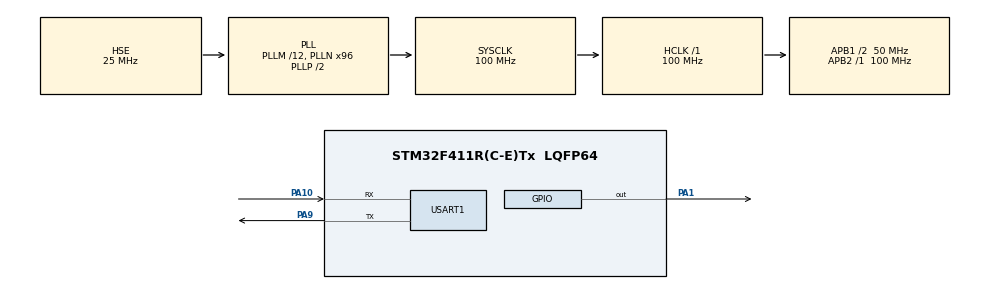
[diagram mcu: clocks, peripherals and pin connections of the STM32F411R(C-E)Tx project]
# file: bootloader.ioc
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Dma.Request0=USART1_RX
Dma.USART1_RX.0.Direction=DMA_PERIPH_TO_MEMORY
Dma.USART1_RX.0.FIFOMode=DMA_FIFOMODE_DISABLE
Dma.USART1_RX.0.Instance=DMA2_Stream2
Dma.USART1_RX.0.MemDataAlignment=DMA_MDATAALIGN_BYTE
Dma.USART1_RX.0.MemInc=DMA_MINC_ENABLE
Dma.USART1_RX.0.Mode=DMA_NORMAL
Dma.USART1_RX.0.PeriphDataAlignment=DMA_PDATAALIGN_BYTE
Dma.USART1_RX.0.PeriphInc=DMA_PINC_DISABLE
Dma.USART1_RX.0.Priority=DMA_PRIORITY_LOW
Mcu.Family=STM32F4
Mcu.Name=STM32F411R(C-E)Tx
Mcu.Package=LQFP64
NVIC.DMA2_Stream2_IRQn=true\:0\:0\:false\:false\:true\:false\:true\:true
NVIC.PriorityGroup=NVIC_PRIORITYGROUP_4
NVIC.USART1_IRQn=true\:0\:0\:false\:false\:true\:false\:true\:true
PA1.Signal=GPIO_Output
PA10.Mode=Asynchronous
PA10.Signal=USART1_RX
PA13.Mode=Serial_Wire
PA13.Signal=SYS_JTMS-SWDIO
PA14.Mode=Serial_Wire
PA14.Signal=SYS_JTCK-SWCLK
PA9.Mode=Asynchronous
PA9.Signal=USART1_TX
PC14-OSC32_IN.Mode=LSE-External-Oscillator
PC14-OSC32_IN.Signal=RCC_OSC32_IN
PC15-OSC32_OUT.Mode=LSE-External-Oscillator
PC15-OSC32_OUT.Signal=RCC_OSC32_OUT
PH0\ -\ OSC_IN.Mode=HSE-External-Oscillator
PH0\ -\ OSC_IN.Signal=RCC_OSC_IN
PH1\ -\ OSC_OUT.Mode=HSE-External-Oscillator
PH1\ -\ OSC_OUT.Signal=RCC_OSC_OUT
ProjectManager.HeapSize=0x200
ProjectManager.StackSize=0x400
ProjectManager.TargetToolchain=MDK-ARM V5.32
RCC.48MHZClocksFreq_Value=50000000
RCC.AHBFreq_Value=100000000
RCC.APB1CLKDivider=RCC_HCLK_DIV2
RCC.APB1Freq_Value=50000000
RCC.APB1TimFreq_Value=100000000
RCC.APB2Freq_Value=100000000
RCC.APB2TimFreq_Value=100000000
RCC.CortexFreq_Value=100000000
RCC.HCLKFreq_Value=100000000
RCC.HSE_VALUE=25000000
RCC.HSI_VALUE=16000000
RCC.PLLM=12
RCC.PLLN=96
RCC.PLLSourceVirtual=RCC_PLLSOURCE_HSE
RCC.SYSCLKFreq_VALUE=100000000
RCC.SYSCLKSource=RCC_SYSCLKSOURCE_PLLCLK
RCC.VCOOutputFreq_Value=200000000
USART1.VirtualMode=VM_ASYNC
board=custom

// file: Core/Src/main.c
/* USER CODE BEGIN Header */
/**
  ******************************************************************************
  * @file           : main.c
  * @brief          : Main program body
  ******************************************************************************
  * @attention
  *
  * Copyright (c) 2026 STMicroelectronics.
  * All rights reserved.
  *
  * This software is licensed under terms that can be found in the LICENSE file
  * in the root directory of this software component.
  * If no LICENSE file comes with this software, it is provided AS-IS.
  *
  ******************************************************************************
  */
/* USER CODE END Header */
#include "main.h"
#include "dma.h"
#include "usart.h"
#include "gpio.h"

/* USER CODE BEGIN Includes */
#include "string.h"
#include "flash_if.h"
#include "protocol.h"
/* USER CODE END Includes */

/* USER CODE BEGIN PD */
/* After reset, wait this long for an upgrade request before booting the app */
#define BOOT_UPGRADE_WINDOW_MS   5000U
/* USER CODE END PD */

/* USER CODE BEGIN PV */
/* TX self-test array: ASCII part is readable in text mode,
   raw bytes are readable in HEX mode */

/* USER CODE END PV */

void SystemClock_Config(void);
/* USER CODE BEGIN PFP */
static uint8_t Boot_IsAppValid(uint32_t app_addr);
static int flag;
/* USER CODE END PFP */

int main(void)
{

  /* MCU Configuration--------------------------------------------------------*/

  /* Reset of all peripherals, Initializes the Flash interface and the Systick. */
  HAL_Init();

  /* Configure the system clock */
  SystemClock_Config();

  /* Initialize all configured peripherals */
  MX_GPIO_Init();
  MX_DMA_Init();
  MX_USART1_UART_Init();
  /* USER CODE BEGIN 2 */
  /*
   * Boot decision:
   *   1. Run area has a valid image -> wait up to 5 s for an upgrade
   *      request. If no frame arrives, boot the application.
   *   2. Run area is blank/invalid but the storage area holds the factory
   *      image -> erase the run area, copy the storage image there, boot it.
   *   3. Neither area is valid -> stay here and wait for OTA.
   */
  if (Boot_IsAppValid(ADDR_RUN) != 0U)
  {
    uint32_t window_start = HAL_GetTick();

    while ((HAL_GetTick() - window_start) < BOOT_UPGRADE_WINDOW_MS)
    {
      if (RX_flag == 1U)
      {
        break;
      }
    }

    if (RX_flag == 0U)
    {
      Jump_To_RunArea(ADDR_RUN);
    }
  }
  else if (Boot_IsAppValid(ADDR_MEMORY) != 0U)
  {
    /* No application in the run area: restore the factory image. */
    flag = Copy_Firmware();
    HAL_Delay(500);
    if (flag == 0)
    {
      Jump_To_RunArea(ADDR_RUN);
    }
  }

  /* USER CODE END 2 */

  /* Infinite loop */
  /* USER CODE BEGIN WHILE */
  while (1)
  {
		if(RX_flag == 1)
		{
			RX_flag = 0;

			Protocol_Handler(RXbuf, RX_len);

			memset(RXbuf,0,sizeof(RXbuf));
			memset(tx_buf,0,sizeof(tx_buf));

			HAL_UART_Receive_DMA(&huart1, RXbuf, RX_BUF_SIZE);

		}

		if(flag == -1)
			HAL_GPIO_WritePin(GPIOA, GPIO_PIN_1, GPIO_PIN_SET);
		else
			HAL_GPIO_WritePin(GPIOA, GPIO_PIN_1, GPIO_PIN_RESET);

  }
  /* USER CODE END 3 */
}

void SystemClock_Config(void)
{
  RCC_OscInitTypeDef RCC_OscInitStruct = {0};
  RCC_ClkInitTypeDef RCC_ClkInitStruct = {0};

  /** Configure the main internal regulator output voltage
  */
  __HAL_RCC_PWR_CLK_ENABLE();
  __HAL_PWR_VOLTAGESCALING_CONFIG(PWR_REGULATOR_VOLTAGE_SCALE1);

  /** Initializes the RCC Oscillators according to the specified parameters
  * in the RCC_OscInitTypeDef structure.
  */
  RCC_OscInitStruct.OscillatorType = RCC_OSCILLATORTYPE_HSE;
  RCC_OscInitStruct.HSEState = RCC_HSE_ON;
  RCC_OscInitStruct.PLL.PLLState = RCC_PLL_ON;
  RCC_OscInitStruct.PLL.PLLSource = RCC_PLLSOURCE_HSE;
  RCC_OscInitStruct.PLL.PLLM = 12;
  RCC_OscInitStruct.PLL.PLLN = 96;
  RCC_OscInitStruct.PLL.PLLP = RCC_PLLP_DIV2;
  RCC_OscInitStruct.PLL.PLLQ = 4;
  if (HAL_RCC_OscConfig(&RCC_OscInitStruct) != HAL_OK)
  {
    Error_Handler();
  }

  /** Initializes the CPU, AHB and APB buses clocks
  */
  RCC_ClkInitStruct.ClockType = RCC_CLOCKTYPE_HCLK|RCC_CLOCKTYPE_SYSCLK
                              |RCC_CLOCKTYPE_PCLK1|RCC_CLOCKTYPE_PCLK2;
  RCC_ClkInitStruct.SYSCLKSource = RCC_SYSCLKSOURCE_PLLCLK;
  RCC_ClkInitStruct.AHBCLKDivider = RCC_SYSCLK_DIV1;
  RCC_ClkInitStruct.APB1CLKDivider = RCC_HCLK_DIV2;
  RCC_ClkInitStruct.APB2CLKDivider = RCC_HCLK_DIV1;

  if (HAL_RCC_ClockConfig(&RCC_ClkInitStruct, FLASH_LATENCY_3) != HAL_OK)
  {
    Error_Handler();
  }
}

/* USER CODE BEGIN 4 */
/**
  * @brief  Check whether a plausible run-linked image is present.
  * @param  app_addr: image base (ADDR_RUN for the run area, ADDR_MEMORY
  *         for the factory image kept in the storage area)
  * @retval 1 = valid, 0 = invalid/blank
  */
static uint8_t Boot_IsAppValid(uint32_t app_addr)
{
  uint32_t sp    = *(volatile uint32_t *)app_addr;
  uint32_t reset = *(volatile uint32_t *)(app_addr + 4U);

  /* STM32F411: SRAM 0x20000000..0x2001FFFF; initial SP may be 0x20020000 */
  if ((sp < 0x20000000U) || (sp > 0x20020000U))
  {
    return 0U;
  }

  /* Reset vector must point into the application region and have Thumb bit set */
  if ((reset < ADDR_RUN) || (reset >= (ADDR_RUN + SIZE_RUN)) || ((reset & 1U) == 0U))
  {
    return 0U;
  }

  return 1U;
}
/* USER CODE END 4 */

void Error_Handler(void)
{
  __disable_irq();
  while (1)
  {
  }
}
